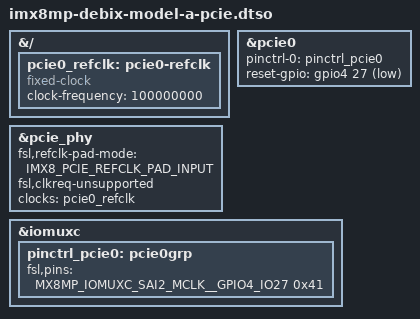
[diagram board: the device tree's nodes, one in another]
// SPDX-License-Identifier: (GPL-2.0+ OR MIT)
/*
 * PCIe Gen3 x1 on the DEBIX Model A FPC connector (J18).
 *
 * The 100 MHz reference clock comes from an external source into the
 * SoC clock pad. CLKREQ# shares the I2C4_SCL pad with the EEPROM and
 * RTC bus, so CLKREQ# is not used.
 */

/dts-v1/;
/plugin/;

#include <dt-bindings/gpio/gpio.h>
#include <dt-bindings/phy/phy-imx8-pcie.h>
#include "../imx8mp-pinfunc.h"

&{/} {
	pcie0_refclk: pcie0-refclk {
		compatible = "fixed-clock";
		#clock-cells = <0>;
		clock-frequency = <100000000>;
	};
};

&pcie_phy {
	fsl,refclk-pad-mode = <IMX8_PCIE_REFCLK_PAD_INPUT>;
	fsl,clkreq-unsupported;
	clocks = <&pcie0_refclk>;
	clock-names = "ref";
	status = "okay";
};

&pcie0 {
	pinctrl-names = "default";
	pinctrl-0 = <&pinctrl_pcie0>;
	reset-gpio = <&gpio4 27 GPIO_ACTIVE_LOW>;
	status = "okay";
};

&iomuxc {
	pinctrl_pcie0: pcie0grp {
		fsl,pins = <
			MX8MP_IOMUXC_SAI2_MCLK__GPIO4_IO27		0x41
		>;
	};
};
